# MKV44F15 register map
Vendor: Freescale Semiconductor, Inc.; Series: Kinetis_V; File version: 1.6
CPU: CM4 r0p1, little endian, no MPU, FPU, VTOR, 4 interrupt priority bits
Registers are 8-bit, read-write, reset 0x0 unless marked. A register's access mark holds for its fields unless they carry their own. Offsets are from the block's base; [hi:lo] are bit positions; {n}, {i} and the like mark numbered series.

## SIM — System Integration Module
Base 0x40047000; register names take the prefix SIM_
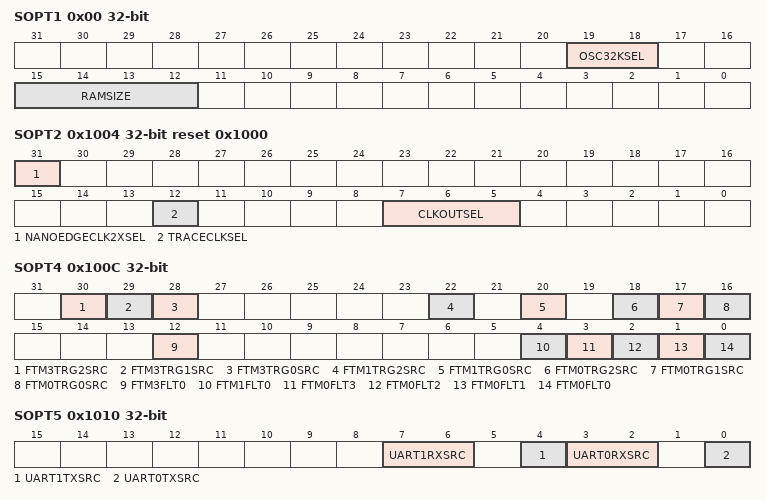
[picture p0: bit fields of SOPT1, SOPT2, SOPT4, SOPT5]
0x00 SOPT1 32-bit (reset mask 0xFFFF0FFF) — System Options Register 1
  [19:18] OSC32KSEL — 32K oscillator clock select
    0=System oscillator (OSC32KCLK); 3=LPO 1 kHz
  [15:12] RAMSIZE ro
    3=16 KB; 5=32 KB
0x1004 SOPT2 32-bit reset 0x1000 — System Options Register 2
  [31] NANOEDGECLK2XSEL — Nanoedge clock(PWM 2x clock) select
    0=MCGPLLCLK; 1=MCGPLLCLK2X
  [12] TRACECLKSEL — Debug trace clock select
    0=MCGOUTCLK; 1=Core/system clock
  [7:5] CLKOUTSEL — CLKOUT select
    2=Flash clock; 3=LPO clock (1 kHz); 4=MCGIRCLK; 5=OSCERCLK_UNDIV; 6=OSCERCLK
0x100C SOPT4 32-bit — System Options Register 4
  [30] FTM3TRG2SRC — FlexTimer 3 Hardware Trigger 2 Source Select
    0=FTM3_FLT0 pin drives FTM3 hardware trigger 2; 1=XBARA output 37 drives FTM3 hardware trigger 2
  [29] FTM3TRG1SRC — FlexTimer 3 Hardware Trigger 1 Source Select
    0=PDB1 output trigger drives FTM3 hardware trigger 1; 1=FTM1 channel match drives FTM3 hardware trigger 1
  [28] FTM3TRG0SRC — FlexTimer 3 Hardware Trigger 0 Source Select
    0=CMP0 output drives FTM3 hardware trigger 0; 1=FTM1 channel match drives FTM3 hardware trigger 0
  [22] FTM1TRG2SRC — FlexTimer 1 Hardware Trigger 2 Source Select
    0=FTM1_FLT0 pin drives FTM1 hardware trigger 2; 1=XBARA output 35 drives FTM1 hardware trigger 2
  [20] FTM1TRG0SRC — FlexTimer 1 Hardware Trigger 0 Source Select
    0=CMP0 output drives FTM1 hardware trigger 0; 1=FTM0 channel match drives FTM1 hardware trigger 0
  [18] FTM0TRG2SRC — FlexTimer 0 Hardware Trigger 2 Source Select
    0=FTM0_FLT0 pin drives FTM0 hardware trigger 2; 1=XBARA output 34 drives FTM0 hardware trigger 2
  [17] FTM0TRG1SRC — FlexTimer 0 Hardware Trigger 1 Source Select
    0=PDB0 output trigger drives FTM0 hardware trigger 1; 1=FTM1 channel match drives FTM0 hardware trigger 1
  [16] FTM0TRG0SRC — FlexTimer 0 Hardware Trigger 0 Source Select
    0=CMP0 output drives FTM0 hardware trigger 0; 1=FTM1 channel match drives FTM0 hardware trigger 0
  [12] FTM3FLT0 — FTM3 Fault 0 Select
    0=FTM3_FLT0 pin; 1=CMP0 out
  [4] FTM1FLT0 — FTM1 Fault 0 Select
    0=FTM1_FLT0 pin; 1=CMP0 out
  [3] FTM0FLT3 — Selects the source of FTM0 fault 3
    0=FTM0_FLT3 pin; 1=XBARA output 49
  [2] FTM0FLT2 — FTM0 Fault 2 Select
    0=FTM0_FLT2 pin; 1=CMP2 out
  [1] FTM0FLT1 — FTM0 Fault 1 Select
    0=FTM0_FLT1 pin; 1=CMP1 out
  [0] FTM0FLT0 — FTM0 Fault 0 Select
    0=FTM0_FLT0 pin; 1=CMP0 out
0x1010 SOPT5 32-bit — System Options Register 5
  [7:6] UART1RXSRC — UART 1 receive data source select
    0=UART1_RX pin; 1=CMP0; 2=CMP1
  [4] UART1TXSRC — UART 1 transmit data source select
    0=UART1_TX pin; 1=UART1_TX pin modulated with FTM1 channel 0 output
  [3:2] UART0RXSRC — UART 0 receive data source select
    0=UART0_RX pin; 1=CMP0; 2=CMP1
  [0] UART0TXSRC — UART 0 transmit data source select
    0=UART0_TX pin; 1=UART0_TX pin modulated with FTM1 channel 0 output
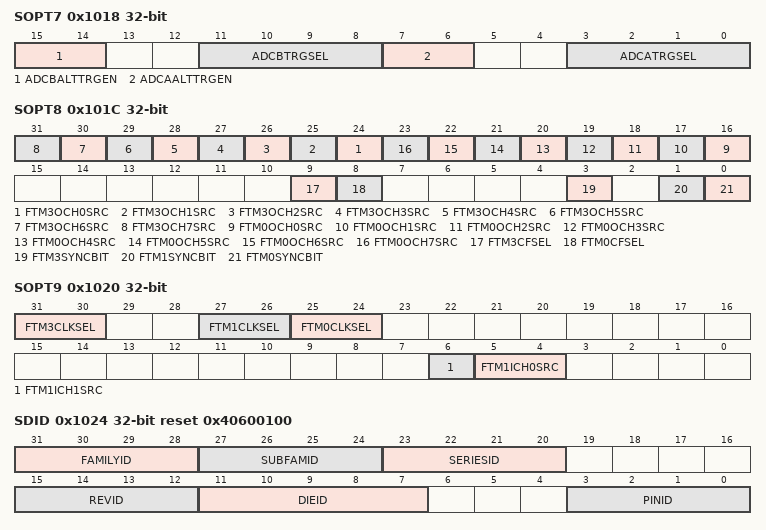
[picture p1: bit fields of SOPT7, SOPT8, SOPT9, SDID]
0x1018 SOPT7 32-bit — System Options Register 7
  [15:14] ADCBALTTRGEN — ADCB alternate trigger enable
    0=XBARA output 13; 1=PDB1 trigger selected for ADCB
  [11:8] ADCBTRGSEL — ADCB trigger select
    1=High speed comparator 0 output; 2=High speed comparator 1 output; 3=High speed comparator 2 output; {v}=PIT trigger {v-4} (v=4..7); 8=FTM0 trigger; 9=FTM1 trigger; 11=FTM3 trigger; 12=XBARA output 41; 14=Low-power timer trigger
  [7:6] ADCAALTTRGEN — ADCA alternate trigger enable
    0=XBARA output 12; 1=PDB0 trigger selected for ADCA
  [3:0] ADCATRGSEL — ADCA trigger select
    0=PDB external trigger pin input (PDB0_EXTRG); 1=High speed comparator 0 output; 2=High speed comparator 1 output; 3=High speed comparator 2 output; {v}=PIT trigger {v-4} (v=4..7); 8=FTM0 trigger; 9=FTM1 trigger; 11=FTM3 trigger; 12=XBARA output 38; 14=Low-power timer trigger
0x101C SOPT8 32-bit — System Options Register 8
  [n+24] FTM3OCH{n}SRC (n=0..7) — FTM3 channel {n} output source
    0=FTM3_CH{n} pin is output of FTM3 channel {n} output; 1=FTM3_CH{n} pin is output of FTM3 channel {n} output modulated by carrier frequency clock, as per FTM3CFSEL
  [n+16] FTM0OCH{n}SRC (n=0..7) — FTM0 channel {n} output source
    0=FTM0_CH{n} pin is output of FTM0 channel {n} output; 1=FTM0_CH{n} pin is output of FTM0 channel {n} output, modulated by carrier frequency clock, as per FTM0CFSEL
  [9] FTM3CFSEL — Carrier frequency selection for FTM3 output channel
    0=FTM1 channel 1 output provides the carrier signal for FTM3 Timer Modulation mode; 1=LPTMR0 prescaler output provides the carrier signal for FTM3 Timer Modulation mode
  [8] FTM0CFSEL — Carrier frequency selection for FTM0 output channel
    0=FTM1 channel 1 output provides the carrier signal for FTM0 Timer Modulation mode; 1=LPTMR0 prescaler output provides the carrier signal for FTM0 Timer Modulation mode
  [3] FTM3SYNCBIT — FTM3 Hardware Trigger 0 Software Synchronization
    0=No effect; 1=Write 1 to assert the TRIG0 input to FTM3, software must clear this bit to allow other trigger sources to assert
  [1] FTM1SYNCBIT — FTM1 Hardware Trigger 0 Software Synchronization
    0=No effect; 1=Write 1 to assert the TRIG0 input to FTM1, software must clear this bit to allow other trigger sources to assert
  [0] FTM0SYNCBIT — FTM0 Hardware Trigger 0 Software Synchronization
    0=No effect; 1=Write 1 to assert the TRIG0 input to FTM0, software must clear this bit to allow other trigger sources to assert
0x1020 SOPT9 32-bit — System Options Register 9
  [31:30] FTM3CLKSEL — FlexTimer 3 External Clock Pin Select
    0=FTM3 external clock driven by FTM_CLK0 pin; 1=FTM3 external clock driven by FTM_CLK1 pin; 2=FTM3 external clock driven by FTM_CLK2 pin
  [27:26] FTM1CLKSEL — FlexTimer 1 External Clock Pin Select
    0=FTM1 external clock driven by FTM_CLK0 pin; 1=FTM1 external clock driven by FTM_CLK1 pin; 2=FTM1 external clock driven by FTM_CLK2 pin
  [25:24] FTM0CLKSEL — FlexTimer 0 External Clock Pin Select
    0=FTM0 external clock driven by FTM_CLK0 pin; 1=FTM0 external clock driven by FTM_CLK1 pin; 2=FTM0 external clock driven by FTM_CLK2 pin
  [6] FTM1ICH1SRC — FTM1 channel 0 input capture source select
    0=FTM1_CH1 signal; 1=Exclusive OR of FTM1_CH1, FTM1_CH0 and XBARA output 42
  [5:4] FTM1ICH0SRC — FTM1 channel 0 input capture source select
    0=FTM1_CH0 signal; 1=CMP0 output; 2=CMP1 output
0x1024 SDID 32-bit ro reset 0x40600100 (reset mask 0xF0FF0FF0) — System Device Identification Register
  [31:28] FAMILYID — Kinetis Family ID
    4=Kinetis family of this device. This is the Vseries.
  [27:24] SUBFAMID — Kinetis Sub-Family ID
    0=KVx0 Subfamily (FlexTimer & MC_ADC); 1=KVx1 Subfamily (FlexTimer & HS_ADC); 2=KVx2 Subfamily (Reserved); 3=KVx3 Subfamily (eFlexPWM & MC_ADC); 4=KVx4 Subfamily (eFlexPWM & HS_ADC); 5=KVx5 Subfamily (eFlexPWM with FlexTimer & MC_ADC); 6=KVx6 Subfamily (eFlexPWM with FlexTimer & HS_ADC)
  [23:20] SERIESID — Kinetis Series ID
    0=Kinetis K series; 1=Kinetis L series; 5=Kinetis W series; 6=Kinetis V series
  [15:12] REVID — Device revision number
  [11:7] DIEID — Device die number
  [3:0] PINID — Pincount identification
    4=48-pin; 5=64-pin; 8=100-pin
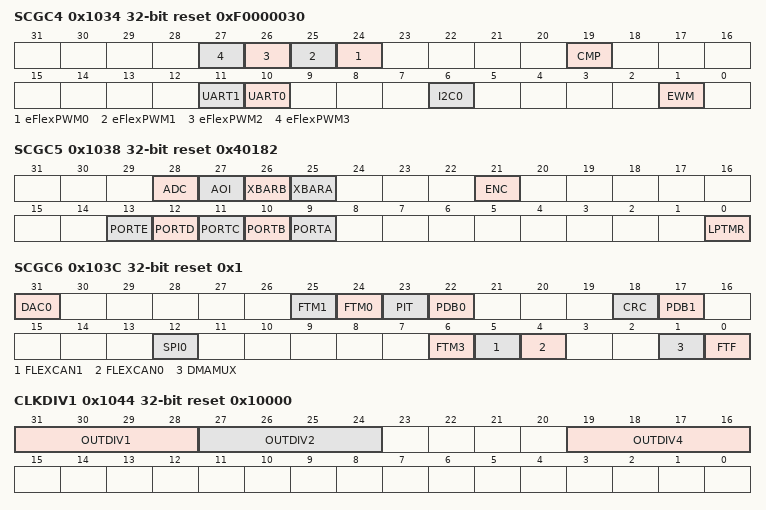
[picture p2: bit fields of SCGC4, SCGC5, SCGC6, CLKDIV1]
0x1034 SCGC4 32-bit reset 0xF0000030 — System Clock Gating Control Register 4
  [all] fields
    0=Clock disabled; 1=Clock enabled
  [n+24] eFlexPWM{n} (n=0..3) — eFlexPWM submodule {n} Clock Gate Control
  [19] CMP — Comparators Clock Gate Control
  [11] UART1 — UART1 Clock Gate Control
  [10] UART0 — UART0 Clock Gate Control
  [6] I2C0 — I2C0 Clock Gate Control
  [1] EWM — EWM Clock Gate Control
0x1038 SCGC5 32-bit reset 0x40182 — System Clock Gating Control Register 5
  [28] ADC — ADC Clock Gate Control
    0=Clock disabled; 1=Clock enabled
  [27] AOI — AOI Clock Gate Control
    0=Clock disabled; 1=Clock enabled
  [26] XBARB — XBARB Clock Gate Control
    0=Clock disabled; 1=Clock enabled
  [25] XBARA — XBARA Clock Gate Control
    0=Clock disabled; 1=Clock enabled
  [21] ENC — This bit controls the clock gate to the ENC module.
    0=Clock disabled; 1=Clock enabled
  [13] PORTE — Port E Clock Gate Control
    0=Clock disabled; 1=Clock enabled
  [12] PORTD — Port D Clock Gate Control
    0=Clock disabled; 1=Clock enabled
  [11] PORTC — Port C Clock Gate Control
    0=Clock disabled; 1=Clock enabled
  [10] PORTB — Port B Clock Gate Control
    0=Clock disabled; 1=Clock enabled
  [9] PORTA — Port A Clock Gate Control
    0=Clock disabled; 1=Clock enabled
  [0] LPTMR — Low Power Timer Access Control
    0=Access disabled; 1=Access enabled
0x103C SCGC6 32-bit reset 0x1 — System Clock Gating Control Register 6
  [all] fields
    0=Clock disabled; 1=Clock enabled
  [31] DAC0 — DAC0 Clock Gate Control
  [25] FTM1 — FTM1 Clock Gate Control
  [24] FTM0 — FTM0 Clock Gate Control
  [23] PIT — PIT Clock Gate Control
  [22] PDB0 — PDB0 Clock Gate Control
  [18] CRC — CRC Clock Gate Control
  [17] PDB1 — PDB1 Clock Gate Control
  [12] SPI0 — SPI0 Clock Gate Control
  [6] FTM3 — FTM3 Clock Gate Control
  [5] FLEXCAN1 — FlexCAN1 Clock Gate Control
  [4] FLEXCAN0 — FlexCAN0 Clock Gate Control
  [1] DMAMUX — DMA Mux Clock Gate Control
  [0] FTF — Flash Memory Clock Gate Control
0x1040 SCGC7 32-bit reset 0x100 — System Clock Gating Control Register 7
  [8] DMA — DMA Clock Gate Control
    0=Clock disabled; 1=Clock enabled
0x1044 CLKDIV1 32-bit reset 0x10000 — System Clock Divider Register 1
  [all] fields
    {v}=Divide-by-{v+1} (v=0..15)
  [31:28] OUTDIV1 — Clock 1 output divider value
  [27:24] OUTDIV2 — Clock 2 output divider value
  [19:16] OUTDIV4 — Clock 4 output divider value
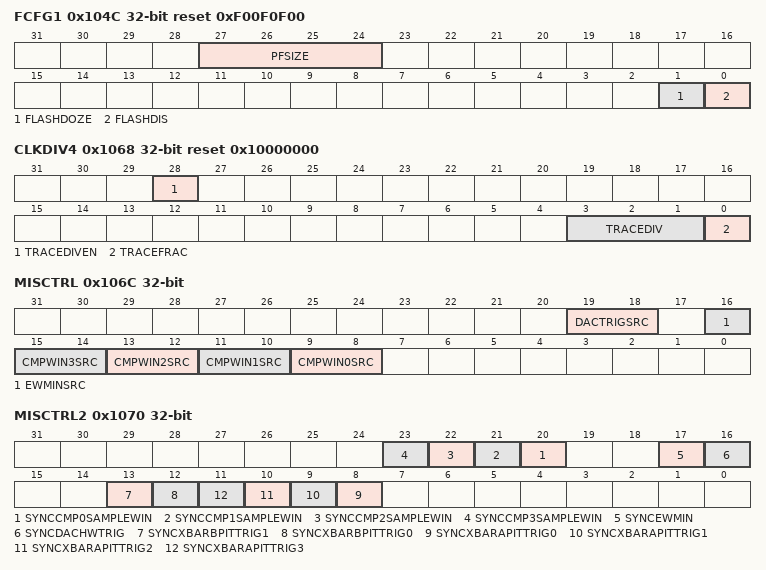
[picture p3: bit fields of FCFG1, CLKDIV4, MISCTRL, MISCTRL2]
0x104C FCFG1 32-bit reset 0xF00F0F00 (reset mask 0xF0FFFFFF) — Flash Configuration Register 1
  [27:24] PFSIZE ro — Program flash size
    3=32 KB of program flash memory; 5=64 KB of program flash memory; 7=128 KB of program flash memory; 9=256 KB of program flash memory
  [1] FLASHDOZE
    0=Flash remains enabled during Wait mode; 1=Flash is disabled for the duration of Wait mode
  [0] FLASHDIS — Flash Disable
    0=Flash is enabled; 1=Flash is disabled
0x1050 FCFG2 32-bit ro reset 0x800000 (reset mask 0x80FFFFFF) — Flash Configuration Register 2
  [30:24] MAXADDR0 — Max address block 0
0x1054 UIDH 32-bit ro reset not defined — Unique Identification Register High
  [31:0] UID — Unique Identification
0x1058 UIDMH 32-bit ro reset not defined — Unique Identification Register Mid-High
  [31:0] UID — Unique Identification
0x105C UIDML 32-bit ro reset not defined — Unique Identification Register Mid Low
  [31:0] UID — Unique Identification
0x1060 UIDL 32-bit ro reset not defined — Unique Identification Register Low
  [31:0] UID — Unique Identification
0x1068 CLKDIV4 32-bit reset 0x10000000 — System Clock Divider Register 4
  [28] TRACEDIVEN — Debug Trace Divider Control
    0=Debug trace divider disabled; 1=Debug trace divider enabled
  [3:1] TRACEDIV — Trace clock divider divisor
  [0] TRACEFRAC — Trace clock divider fraction
0x106C MISCTRL 32-bit — Miscellaneous Control Register
  [19:18] DACTRIGSRC — DAC0 Hardware Trigger Input Source
    0=XBARA output 15; 1=DAC0 can be triggered by both PDB0 interval trigger 0 and PDB1 interval trigger 0; 2=PDB0 interval trigger 0; 3=PDB1 interval trigger 0
  [16] EWMINSRC — EWM_IN Source
    0=XBARA output 58; 1=EWM_IN pin
  [2n+9:2n+8] CMPWIN{n}SRC (n=0..3) — CMP Sample/Window Input {n} Source
    0=XBARA output {n+16}; 1=CMP{n} Sample/Window input is driven by both PDB0 and PDB1 pluse-out channel {n}; 2=PDB0 pluse-out channel {n}; 3=PDB1 pluse-out channel {n}
0x1070 MISCTRL2 32-bit — Miscellaneous Control Register 2
  [all] fields
    0=Disable, bypass synchronizer; 1=Enable
  [n+20] SYNCCMP{n}SAMPLEWIN (n=0..3) — Synchronize XBARA's output for CMP{n}'s Sample/Window Input with flash/slow clock
  [17] SYNCEWMIN — Synchronize XBARA's output for EWM's ewm_in with flash/slow clock
  [16] SYNCDACHWTRIG — Synchronize XBARA's output for DAC Hardware Trigger with flash/slow clock
  [13] SYNCXBARBPITTRIG1 — Synchronize XBARB's Input PIT Trigger 1 with fast clock
  [12] SYNCXBARBPITTRIG0 — Synchronize XBARB's Input PIT Trigger 0 with fast clock
  [n+8] SYNCXBARAPITTRIG{n} (n=0..3) — Synchronize XBARA's Input PIT Trigger {n} with fast clock
0x1100 WDOGC 32-bit — WDOG Control Register
  [1] WDOGCLKS — WDOG Clock Select
    0=Internal 1 kHz clock is source to WDOG2008; 1=MCGIRCLK is source to WDOG2008
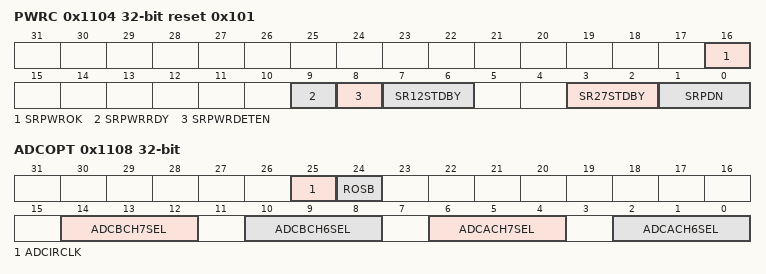
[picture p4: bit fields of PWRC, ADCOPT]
0x1104 PWRC 32-bit reset 0x101 — Power Control Register
  [16] SRPWROK ro — Nanoedge PMC Status
    0=Power supply for nanoedge isn't ready; 1=Power supply for nanoedge is OK
  [9] SRPWRRDY — Nanoedge PMC POWER Ready
    0=Not ready; 1=Assert PMC power output ready
  [8] SRPWRDETEN — Nanoedge PMC POWER Dectect Enable
    0=Disable; 1=Enable
  [7:6] SR12STDBY — Nanoedge Regulator 1.2 V Supply Standby Control
    0=Nanoedge regulator 1.2 V supply placed in normal mode; 1=Nanoedge regulator 1.2 V supply placed in standby mode; 2=Nanoedge regulator 1.2 V supply placed in normal mode and SR12STDBY is write protected until chip reset; 3=Nanoedge regulator 1.2 V supply placed in standby mode and SR12STDBY is write protected until chip reset
  [3:2] SR27STDBY — Nanoedge Regulator 2.7 V Supply Standby Control
    0=Nanoedge regulator 2.7 V placed in normal mode; 1=Nanoedge regulator 2.7 V placed in standby mode; 2=Nanoedge regulator 2.7 V supply placed in normal mode and SR27STDBY is write protected until chip reset; 3=Nanoedge regulator 2.7 V supply placed in standby mode and SR27STDBY is write protected until chip reset
  [1:0] SRPDN — Nanoedge Regulator 2.7V and 1.2V Supply Powerdown Control
    0=Nanoedge regulator placed in normal mode; 1=Nanoedge regulator placed in powerdown mode; 2=Nanoedge regulator placed in normal mode and SRPDN is write protected until chip reset; 3=Nanoedge regulator placed in powerdown mode and SRPDN is write protected until chip reset
0x1108 ADCOPT 32-bit — ADC Channel 6/7 Mux Control Register
  [25] ADCIRCLK ro — ADC Clock Status
    0=ADC clock is fast peripherial clock; 1=ADC clock is MCGIRCLK
  [24] ROSB — Enable ADC low current Mode
    0=Disable ADC low current mode; 1=Enable ADC low current mode
  [14:12] ADCBCH7SEL — ADCB MUX1 selection for ADCB channel 7
    0=ADCB MUX1's channel a; 1=ADCB MUX1's channel b; 2=ADCB MUX1's channel c; 3=ADCB MUX1's channel d; 4=ADCB MUX1's channel e; 5=ADCB MUX1's channel f; 6=ADCB MUX1's channel g
  [10:8] ADCBCH6SEL — ADCB MUX1 selection for ADCB channel 6
    0=ADCB MUX0's channel a; 1=ADCB MUX0's channel b; 2=ADCB MUX0's channel c; 3=ADCB MUX0's channel d; 4=ADCB MUX0's channel e; 5=ADCB MUX0's channel f; 6=ADCB MUX0's channel g; 7=PMC 1V
  [6:4] ADCACH7SEL — ADCA MUX1 selection for ADCA channel 7
    0=ADCA MUX1's channel a; 1=ADCA MUX1's channel b; 2=ADCA MUX1's channel c; 4=ADCA MUX1's channel e; 5=ADCA MUX1's channel f; 6=ADCA MUX1's channel g; 7=PMC 1V
  [2:0] ADCACH6SEL — ADCA MUX0 selection for ADCA channel 6
    0=ADCA MUX0's channel a; 1=ADCA MUX0's channel b; 2=ADCA MUX0's channel c; 3=ADCA MUX0's channel d; 4=ADCA MUX0's channel e; 6=ADCA MUX0's channel g
